VERSION ""

NS_ :

BS_:

BU_: DCDCwithOBC MCU BMS EMS HCU Gateway

BO_ 726 BMS_7: 8 MCU
 SG_ BMS_BatteryPackSOC : 24|10@1+ (0.1,0) [0|100] "%"  DCDCwithOBC

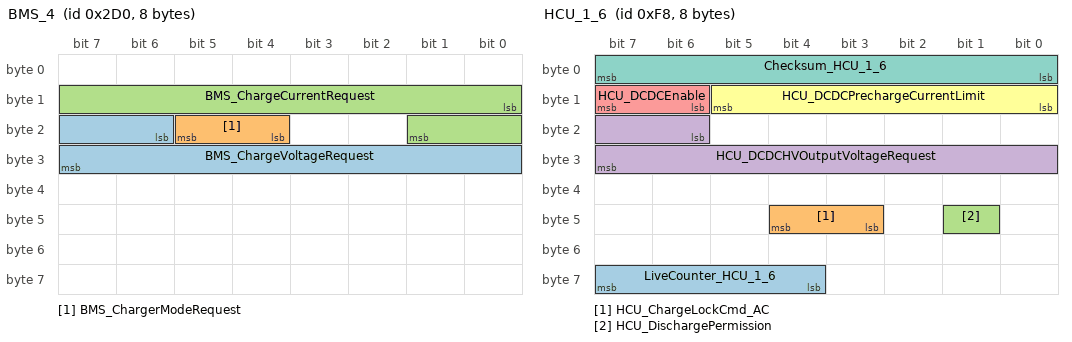
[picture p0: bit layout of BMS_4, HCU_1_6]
BO_ 720 BMS_4: 8 MCU
 SG_ BMS_ChargeVoltageRequest : 22|10@1+ (1,0) [0|750] "V"  DCDCwithOBC
 SG_ BMS_ChargerModeRequest : 20|2@1+ (1,0) [0|3] ""  DCDCwithOBC
 SG_ BMS_ChargeCurrentRequest : 8|10@1+ (0.1,-100) [-100|0] "A"  DCDCwithOBC

BO_ 240 BMS_1: 8 MCU
 SG_ BMS_BatteryPackCurrent : 24|15@1+ (0.1,-1600) [-1600|1600] "A"  DCDCwithOBC

BO_ 708 HCU_1_8: 8 HCU
 SG_ HCU_ChargeConnectStatus : 36|4@1+ (1,0) [0|15] ""  DCDCwithOBC

BO_ 248 HCU_1_6: 8 HCU
 SG_ LiveCounter_HCU_1_6 : 60|4@1+ (1,0) [0|15] "Pulse"  DCDCwithOBC
 SG_ HCU_ChargeLockCmd_AC : 43|2@1+ (1,0) [0|3] ""  DCDCwithOBC
 SG_ HCU_DischargePermission : 41|1@1+ (1,0) [0|1] ""  DCDCwithOBC
 SG_ HCU_DCDCHVOutputVoltageRequest : 22|10@1+ (1,0) [0|750] "V"  DCDCwithOBC
 SG_ HCU_DCDCEnable : 14|2@1+ (1,0) [0|3] ""  DCDCwithOBC
 SG_ HCU_DCDCPrechargeCurrentLimit : 8|6@1+ (3,0) [0|180] "A"  DCDCwithOBC
 SG_ Checksum_HCU_1_6 : 0|8@1+ (1,0) [0|255] ""  DCDCwithOBC

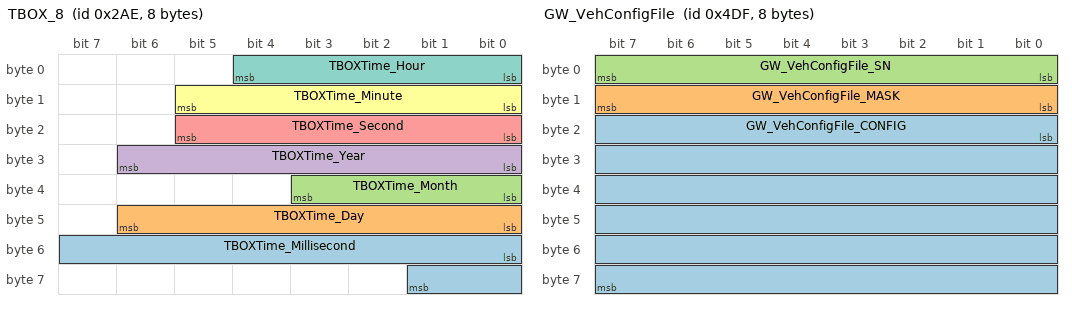
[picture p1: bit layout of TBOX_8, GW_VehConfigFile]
BO_ 686 TBOX_8: 8 Gateway
 SG_ TBOXTime_Millisecond : 48|10@1+ (1,0) [0|1000] "ms"  DCDCwithOBC
 SG_ TBOXTime_Day : 40|7@1+ (1,1) [1|31] "day"  DCDCwithOBC
 SG_ TBOXTime_Month : 32|4@1+ (1,1) [1|12] "month"  DCDCwithOBC
 SG_ TBOXTime_Year : 24|7@1+ (1,2011) [2011|2136] "year"  DCDCwithOBC
 SG_ TBOXTime_Second : 16|6@1+ (1,0) [0|59] "second"  DCDCwithOBC
 SG_ TBOXTime_Minute : 8|6@1+ (1,0) [0|59] "minute"  DCDCwithOBC
 SG_ TBOXTime_Hour : 0|5@1+ (1,0) [0|23] "hour"  DCDCwithOBC

BO_ 656 IC_1: 8 Gateway
 SG_ OdometerValue : 24|25@1+ (0.1,0) [0|3355443] "km"  DCDCwithOBC

BO_ 1247 GW_VehConfigFile: 8 Gateway
 SG_ GW_VehConfigFile_CONFIG : 16|48@1+ (1,0) [0|281474976710655] ""  DCDCwithOBC
 SG_ GW_VehConfigFile_MASK : 8|8@1+ (1,0) [0|255] ""  DCDCwithOBC
 SG_ GW_VehConfigFile_SN : 0|8@1+ (1,0) [0|254] ""  DCDCwithOBC

BO_ 688 GW_Config: 8 Gateway
 SG_ GW_OTAMode : 16|3@1+ (1,0) [0|7] ""  DCDCwithOBC

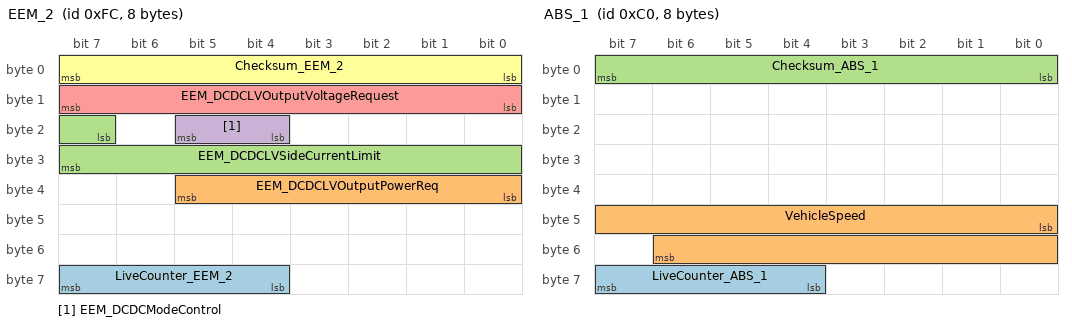
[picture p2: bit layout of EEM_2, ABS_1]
BO_ 252 EEM_2: 8 Gateway
 SG_ LiveCounter_EEM_2 : 60|4@1+ (1,0) [0|15] "Pulse"  DCDCwithOBC
 SG_ EEM_DCDCLVOutputPowerReq : 32|6@1+ (0.1,0) [0|3] "KW"  DCDCwithOBC
 SG_ EEM_DCDCLVSideCurrentLimit : 23|9@1+ (1,0) [0|400] "A"  DCDCwithOBC
 SG_ EEM_DCDCModeControl : 20|2@1+ (1,0) [0|3] ""  DCDCwithOBC
 SG_ EEM_DCDCLVOutputVoltageRequest : 8|8@1+ (0.1,0) [0|20] "V"  DCDCwithOBC
 SG_ Checksum_EEM_2 : 0|8@1+ (1,0) [0|255] ""  DCDCwithOBC

BO_ 562 BCM1_2: 8 Gateway
 SG_ PowerMode : 4|4@1+ (1,0) [0|15] ""  DCDCwithOBC

BO_ 192 ABS_1: 8 Gateway
 SG_ LiveCounter_ABS_1 : 60|4@1+ (1,0) [0|15] ""  DCDCwithOBC
 SG_ VehicleSpeed : 40|15@1+ (0.01,0) [0|327.65] "km/h"  DCDCwithOBC
 SG_ Checksum_ABS_1 : 0|8@1+ (1,0) [0|255] ""  DCDCwithOBC

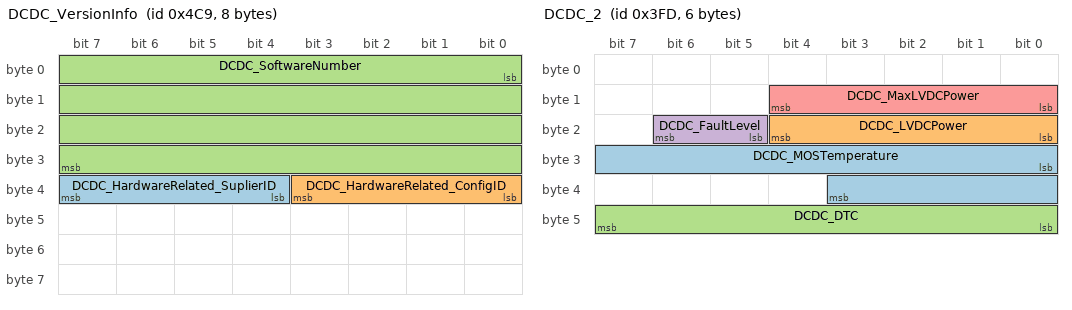
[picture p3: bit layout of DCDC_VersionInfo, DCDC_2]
BO_ 1225 DCDC_VersionInfo: 8 DCDCwithOBC
 SG_ DCDC_HardwareRelated_SuplierID : 36|4@1+ (1,0) [0|15] ""  Gateway
 SG_ DCDC_HardwareRelated_ConfigID : 32|4@1+ (1,0) [0|15] ""  Gateway
 SG_ DCDC_SoftwareNumber : 0|32@1+ (1,0) [0|4294967295] ""  Gateway

BO_ 1021 DCDC_2: 6 DCDCwithOBC
 SG_ DCDC_MOSTemperature : 24|12@1+ (0.1,-40) [-40|200] "¡æ" Vector__XXX
 SG_ DCDC_LVDCPower : 16|5@1+ (0.1,0) [0|3] "kW"  Gateway
 SG_ DCDC_DTC : 40|8@1+ (1,0) [0|255] ""  Gateway
 SG_ DCDC_FaultLevel : 21|2@1+ (1,0) [0|3] ""  Gateway
 SG_ DCDC_MaxLVDCPower : 8|5@1+ (0.1,0) [0|3] "kW"  Gateway

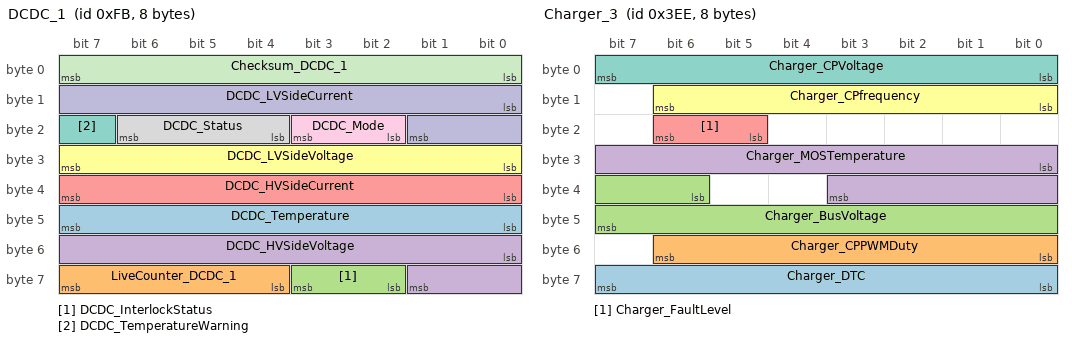
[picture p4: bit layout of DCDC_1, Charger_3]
BO_ 251 DCDC_1: 8 DCDCwithOBC
 SG_ DCDC_Temperature : 40|8@1+ (1,-40) [-40|210] "¡æ"  HCU,Gateway
 SG_ LiveCounter_DCDC_1 : 60|4@1+ (1,0) [0|15] "Pulse"  MCU,HCU
 SG_ DCDC_InterlockStatus : 58|2@1+ (1,0) [0|3] ""  Gateway
 SG_ DCDC_HVSideVoltage : 48|10@1+ (1,0) [0|750] "V"  MCU,HCU,Gateway
 SG_ DCDC_HVSideCurrent : 32|8@1+ (0.2,-20) [-20|20] "A"  MCU,HCU,Gateway
 SG_ DCDC_LVSideVoltage : 24|8@1+ (0.1,0) [0|20] "V"  MCU,HCU,Gateway
 SG_ DCDC_TemperatureWarning : 23|1@1+ (1,0) [0|1] ""  Gateway
 SG_ DCDC_Status : 20|3@1+ (1,0) [0|7] ""  MCU,HCU,Gateway
 SG_ DCDC_Mode : 18|2@1+ (1,0) [0|3] ""  Gateway
 SG_ DCDC_LVSideCurrent : 8|10@1+ (1,-400) [-400|400] "A"  MCU,HCU,Gateway
 SG_ Checksum_DCDC_1 : 0|8@1+ (1,0) [0|255] ""  MCU,HCU

BO_ 1006 Charger_3: 8 DCDCwithOBC
 SG_ Charger_DTC : 56|8@1+ (1,0) [0|255] ""  Gateway
 SG_ Charger_CPPWMDuty : 48|7@1+ (1,0) [0|100] "%"  Gateway
 SG_ Charger_BusVoltage : 38|10@1+ (1,0) [0|1000] "V"  Gateway
 SG_ Charger_MOSTemperature : 24|12@1+ (0.1,-40) [-40|200] "¡æ"  Gateway
 SG_ Charger_FaultLevel : 21|2@1+ (1,0) [0|3] ""  Gateway
 SG_ Charger_CPfrequency : 8|7@1+ (10,0) [0|1200] "Hz"  Gateway
 SG_ Charger_CPVoltage : 0|8@1+ (0.1,0) [0|20] "V"  Gateway

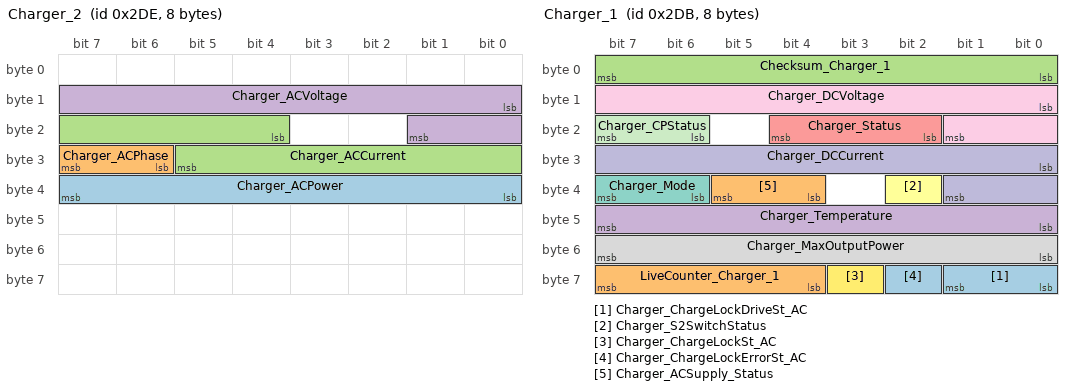
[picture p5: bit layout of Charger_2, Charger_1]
BO_ 734 Charger_2: 8 DCDCwithOBC
 SG_ Charger_ACPower : 32|8@1+ (0.1,0) [0|20] "kW"  Gateway
 SG_ Charger_ACPhase : 30|2@1+ (1,0) [0|3] ""  Gateway
 SG_ Charger_ACCurrent : 20|10@1+ (0.1,0) [0|100] "A"  Gateway
 SG_ Charger_ACVoltage : 8|10@1+ (1,0) [0|750] "V"  Gateway

BO_ 731 Charger_1: 8 DCDCwithOBC
 SG_ Charger_ChargeLockDriveSt_AC : 56|2@1+ (1,0) [0|3] "" Vector__XXX
 SG_ LiveCounter_Charger_1 : 60|4@1+ (1,0) [0|15] "Pulse"  BMS,Gateway
 SG_ Checksum_Charger_1 : 0|8@1+ (1,0) [0|255] ""  BMS,Gateway
 SG_ Charger_Temperature : 40|8@1+ (1,-40) [-40|210] "¡æ"  Gateway
 SG_ Charger_Status : 18|3@1+ (1,0) [0|7] ""  BMS,Gateway
 SG_ Charger_S2SwitchStatus : 34|1@1+ (1,0) [0|1] ""  Gateway
 SG_ Charger_Mode : 38|2@1+ (1,0) [0|3] ""  BMS,Gateway
 SG_ Charger_MaxOutputPower : 48|8@1+ (0.1,0) [0|20] "kW"  BMS,Gateway
 SG_ Charger_DCVoltage : 8|10@1+ (1,0) [0|1000] "V"  BMS,Gateway
 SG_ Charger_DCCurrent : 24|10@1+ (0.1,0) [0|100] "A"  BMS,Gateway
 SG_ Charger_CPStatus : 22|2@1+ (1,0) [0|3] ""  Gateway
 SG_ Charger_ChargeLockSt_AC : 59|1@1+ (1,0) [0|1] ""  Gateway
 SG_ Charger_ChargeLockErrorSt_AC : 58|1@1+ (1,0) [0|1] ""  Gateway
 SG_ Charger_ACSupply_Status : 36|2@1+ (1,0) [0|3] ""  Gateway

EV_ EnvKlemme30: 0 [0|1] "" 1 1 DUMMY_NODE_VECTOR0 Vector__XXX;

EV_ EnvKlemme15: 0 [0|1] "" 0 2 DUMMY_NODE_VECTOR0 Vector__XXX;

BA_DEF_ BU_  "NodeLayerModules" STRING ;
BA_DEF_ BO_  "GenMsgILSupport" ENUM  "No","Yes";
BA_DEF_  "NmBaseAddress" HEX 1024 1087;
BA_DEF_ BO_  "GenMsgCycleTime" INT 0 50000;
BA_DEF_ BO_  "GenMsgSendType" ENUM  "Cyclic","NotUsed","NotUsed","NotUsed","NotUsed","NotUsed","NotUsed","IfActive","NoMsgSendType","NotUsed","vector_leerstring";
BA_DEF_ SG_  "GenSigSendType" ENUM  "Cyclic","OnWrite","OnWriteWithRepetition","OnChange","OnChangeWithRepetition","IfActive","IfActiveWithRepetition","NoSigSendType","NotUsed","NotUsed","NotUsed","NotUsed","NotUsed";
BA_DEF_ SG_  "GenSigStartValue" FLOAT 0 100000000000;
BA_DEF_DEF_  "NodeLayerModules" "CANoeILNLVector.dll";
BA_DEF_DEF_  "GenMsgILSupport" "Yes";
BA_DEF_DEF_  "NmBaseAddress" 1024;
BA_DEF_DEF_  "GenMsgCycleTime" 0;
BA_DEF_DEF_  "GenMsgSendType" "NoMsgSendType";
BA_DEF_DEF_  "GenSigSendType" "Cyclic";
BA_DEF_DEF_  "GenSigStartValue" 0;
BA_ "GenMsgSendType" BO_ 726 0;
BA_ "GenMsgCycleTime" BO_ 726 100;
BA_ "GenMsgSendType" BO_ 720 0;
BA_ "GenMsgCycleTime" BO_ 720 100;
BA_ "GenMsgSendType" BO_ 240 0;
BA_ "GenMsgCycleTime" BO_ 240 10;
BA_ "GenMsgSendType" BO_ 708 0;
BA_ "GenMsgCycleTime" BO_ 708 100;
BA_ "GenMsgSendType" BO_ 248 0;
BA_ "GenMsgCycleTime" BO_ 248 10;
BA_ "GenMsgSendType" BO_ 686 0;
BA_ "GenMsgCycleTime" BO_ 686 100;
BA_ "GenMsgSendType" BO_ 656 0;
BA_ "GenMsgCycleTime" BO_ 656 100;
BA_ "GenMsgSendType" BO_ 1247 0;
BA_ "GenMsgCycleTime" BO_ 1247 100;
BA_ "GenMsgSendType" BO_ 688 0;
BA_ "GenMsgCycleTime" BO_ 688 100;
BA_ "GenMsgSendType" BO_ 252 0;
BA_ "GenMsgCycleTime" BO_ 252 10;
BA_ "GenMsgSendType" BO_ 562 0;
BA_ "GenMsgCycleTime" BO_ 562 100;
BA_ "GenMsgSendType" BO_ 192 0;
BA_ "GenMsgCycleTime" BO_ 192 100;
BA_ "GenMsgSendType" BO_ 1225 0;
BA_ "GenMsgCycleTime" BO_ 1225 5000;
BA_ "GenMsgSendType" BO_ 1021 0;
BA_ "GenMsgCycleTime" BO_ 1021 1000;
BA_ "GenMsgSendType" BO_ 251 0;
BA_ "GenMsgCycleTime" BO_ 251 10;
BA_ "GenMsgSendType" BO_ 1006 0;
BA_ "GenMsgCycleTime" BO_ 1006 1000;
BA_ "GenMsgSendType" BO_ 734 0;
BA_ "GenMsgCycleTime" BO_ 734 1000;
BA_ "GenMsgSendType" BO_ 731 0;
BA_ "GenMsgCycleTime" BO_ 731 100;
BA_ "GenSigStartValue" SG_ 720 BMS_ChargeCurrentRequest 1000;
BA_ "GenSigStartValue" SG_ 240 BMS_BatteryPackCurrent 16000;
BA_ "GenSigStartValue" SG_ 1021 DCDC_MOSTemperature 400;
BA_ "GenSigStartValue" SG_ 251 DCDC_Temperature 40;
BA_ "GenSigStartValue" SG_ 251 DCDC_HVSideCurrent 100;
BA_ "GenSigStartValue" SG_ 251 DCDC_LVSideCurrent 400;
BA_ "GenSigStartValue" SG_ 1006 Charger_MOSTemperature 400;
BA_ "GenSigStartValue" SG_ 731 Charger_Temperature 40;
VAL_ 720 BMS_ChargerModeRequest 3 "Reserved" 2 "Voltage Mode" 1 "Current Mode" 0 "No Output" ;
VAL_ 708 HCU_ChargeConnectStatus 15 "Reserved" 14 "Unusual connect" 13 "Reserved" 12 "Reserved" 11 "Reserved" 10 "Reserved" 9 "Reserved" 8 "Reserved" 7 "Reserved" 6 "AC Discharge" 5 "63A AC Connect" 4 "DC connect" 3 "10A AC connect" 2 "16A AC connect" 1 "32A AC connect" 0 "Disconnect" ;
VAL_ 248 HCU_ChargeLockCmd_AC 3 "Reserved" 2 "Unlock" 1 "Lock" 0 "Inactive" ;
VAL_ 248 HCU_DischargePermission 1 "Permission" 0 "No Permission" ;
VAL_ 248 HCU_DCDCEnable 3 "Boost enable" 2 "Buck enable" 1 "Precharge enable" 0 "Not enable" ;
VAL_ 688 GW_OTAMode 2 "Reserved" 1 "OTA Mode" 0 "Normal Mode" ;
VAL_ 252 EEM_DCDCModeControl 3 "Output Power mode" 2 "Output Current Mode" 1 "Output Voltage Mode" 0 "No Output" ;
VAL_ 562 PowerMode 15 "Invalid Value" 14 "Reserved" 13 "Reserved" 12 "Reserved" 11 "Reserved" 10 "Reserved" 9 "Reserved" 8 "Reserved" 7 "Reserved" 6 "Reserved" 5 "Reserved" 4 "IgnitionOn" 3 "Reserved" 2 "Reserved" 1 "Reserved" 0 "Off" ;
VAL_ 1225 DCDC_HardwareRelated_SuplierID 2 "Reserved" 1 "JOYSON" 0 "INVANCE" ;
VAL_ 1225 DCDC_HardwareRelated_ConfigID 1 "Reserved" 0 "PHEV" ;
VAL_ 1021 DCDC_FaultLevel 3 "Level 3" 2 "Level 2" 1 "Level 1" 0 "No Fault" ;
VAL_ 251 DCDC_InterlockStatus 3 "Reserved" 2 "AC not connected" 1 "HV not connected" 0 "Close" ;
VAL_ 251 DCDC_TemperatureWarning 1 "Warning" 0 "No warning" ;
VAL_ 251 DCDC_Status 7 "Reserved" 6 "BuckwithDerating" 5 "Critical Fault" 4 "Normal Fault" 3 "Buck" 2 "Precharge" 1 "Standby" 0 "Initial" ;
VAL_ 251 DCDC_Mode 3 "Power Mode" 2 "Voltage Mode" 1 "Current Mode" 0 "No output" ;
VAL_ 1006 Charger_FaultLevel 3 "Level 3" 2 "Level 2" 1 "Level 1" 0 "No Fault" ;
VAL_ 734 Charger_ACPhase 3 "Reserved" 2 "Three-Phase-AC" 1 "Single-Phase-AC" 0 "Standby" ;
VAL_ 731 Charger_ChargeLockDriveSt_AC 3 "Reserved" 2 "Unlock" 1 "Lock" 0 "Inactive" ;
VAL_ 731 Charger_Status 7 "Initial" 6 "Derating(Discharging)" 5 "Derating(Charging)" 4 "Working(Discharging)" 3 "Charger Fault" 2 "Charger Abnormal" 1 "Working(Charging)" 0 "Idle" ;
VAL_ 731 Charger_S2SwitchStatus 1 "Close" 0 "Open" ;
VAL_ 731 Charger_Mode 3 "Power Mode" 2 "Voltage Mode" 1 "Current Mode" 0 "No Output" ;
VAL_ 731 Charger_CPStatus 3 "Prepare" 2 "Abnormal" 1 "Connected" 0 "Disconnect" ;
VAL_ 731 Charger_ChargeLockSt_AC 1 "Locked" 0 "Unlocked" ;
VAL_ 731 Charger_ChargeLockErrorSt_AC 1 "Error" 0 "No error" ;
VAL_ 731 Charger_ACSupply_Status 3 "Reserved" 2 "AC supply abnormal" 1 "No Elec,check supply or cable" 0 "Normal" ;
